AUTOSAR XML (schema 00046)
package /ComponentTypes
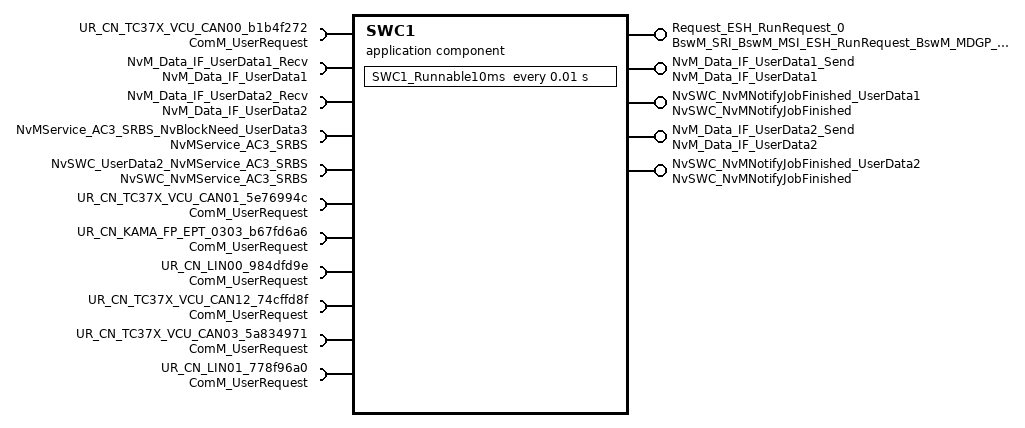
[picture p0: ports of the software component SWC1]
  application sw component type SWC1
    provide port Request_ESH_RunRequest_0: nonqueued-sender-com-spec=requestedMode, provided-interface=BswM_SRI_BswM_MSI_ESH_RunRequest_BswM_MDGP_ESH_RunRequest
    require port UR_CN_TC37X_VCU_CAN00_b1b4f272: required-com-specs=[RequestComMode, GetCurrentComMode, GetMaxComMode, GetRequestedComMode], required-interface=ComM_UserRequest
    provide port NvM_Data_IF_UserData1_Send: nv-provide-com-spec{ram-block-init-value=10 x 0, rom-block-init-value=10 x 0, variable=Element_UserData1}, provided-interface=NvM_Data_IF_UserData1
    require port NvM_Data_IF_UserData1_Recv: nv-require-com-spec{init-value=10 x 0, variable=Element_UserData1}, required-interface=NvM_Data_IF_UserData1
    provide port NvSWC_NvMNotifyJobFinished_UserData1: server-com-spec{operation=JobFinished, queue-length=1}, provided-interface=NvSWC_NvMNotifyJobFinished
    provide port NvM_Data_IF_UserData2_Send: nv-provide-com-spec=Element_UserData2, provided-interface=NvM_Data_IF_UserData2
    require port NvM_Data_IF_UserData2_Recv: nv-require-com-spec=Element_UserData2, required-interface=NvM_Data_IF_UserData2
    provide port NvSWC_NvMNotifyJobFinished_UserData2: server-com-spec{operation=JobFinished, queue-length=1}, provided-interface=NvSWC_NvMNotifyJobFinished
    8 x require port:
      NvMService_AC3_SRBS_NvBlockNeed_UserData3: required-com-specs=[WriteBlock, SetRamBlockStatus, ReadBlock, InvalidateNvBlock, GetErrorStatus, EraseBlock], required-interface=NvMService_AC3_SRBS
      NvSWC_UserData2_NvMService_AC3_SRBS: required-com-specs=[WriteBlock, SetRamBlockStatus, ReadBlock, InvalidateNvBlock, GetErrorStatus, EraseBlock], required-interface=NvSWC_NvMService_AC3_SRBS
      UR_CN_TC37X_VCU_CAN01_5e76994c: required-com-specs=[RequestComMode, GetCurrentComMode, GetMaxComMode, GetRequestedComMode], required-interface=ComM_UserRequest
      UR_CN_KAMA_FP_EPT_0303_b67fd6a6: required-com-specs=[RequestComMode, GetCurrentComMode, GetMaxComMode, GetRequestedComMode], required-interface=ComM_UserRequest
      UR_CN_LIN00_984dfd9e: required-com-specs=[RequestComMode, GetCurrentComMode, GetMaxComMode, GetRequestedComMode], required-interface=ComM_UserRequest
      UR_CN_TC37X_VCU_CAN12_74cffd8f: required-com-specs=[RequestComMode, GetCurrentComMode, GetMaxComMode, GetRequestedComMode], required-interface=ComM_UserRequest
      UR_CN_TC37X_VCU_CAN03_5a834971: required-com-specs=[RequestComMode, GetCurrentComMode, GetMaxComMode, GetRequestedComMode], required-interface=ComM_UserRequest
      UR_CN_LIN01_778f96a0: required-com-specs=[RequestComMode, GetCurrentComMode, GetMaxComMode, GetRequestedComMode], required-interface=ComM_UserRequest
    behavior SWC1_InternalBehavior
      ar-typed-per-instance-memorys:
        data NvBlockNeed_UserData3_MirrorBlock: sw-calibration-access=READ-ONLY, type=NvM_Array10Bytes
      init event SWC1_InitEvent: start-on-event=SWC1_Init
      timing event TMT_SWC1_Runnable10ms: start-on-event=SWC1_Runnable10ms, period=0.01
      operation invoked event OIT_NvSWC_NvMNotifyJobFinished_UserData1_JobFinished_NvSWC_NvMNotifyJobFinished_UserData1_JobFinished: start-on-event=NvSWC_NvMNotifyJobFinished_UserData1_JobFinished, operation=NvSWC_NvMNotifyJobFinished_UserData1.JobFinished
      operation invoked event OIT_NvSWC_NvMNotifyJobFinished_UserData2_JobFinished_NvSWC_NvMNotifyJobFinished_UserData2_JobFinished: start-on-event=NvSWC_NvMNotifyJobFinished_UserData2_JobFinished, operation=NvSWC_NvMNotifyJobFinished_UserData2.JobFinished
      4 x runnable:
        SWC1_Init
          data-send-points:
            access SEND_Request_ESH_RunRequest_0_requestedMode: accessed-variable=Request_ESH_RunRequest_0.requestedMode
        SWC1_Runnable10ms
          data-receive-point-by-arguments:
            access REC_NvM_Data_IF_UserData1_Recv_Element_UserData1: accessed-variable=NvM_Data_IF_UserData1_Recv.Element_UserData1
            access REC_NvM_Data_IF_UserData2_Recv_Element_UserData2: accessed-variable=NvM_Data_IF_UserData2_Recv.Element_UserData2
          data-send-points:
            access SEND_NvM_Data_IF_UserData1_Send_Element_UserData1: accessed-variable=NvM_Data_IF_UserData1_Send.Element_UserData1
            access SEND_NvM_Data_IF_UserData2_Send_Element_UserData2: accessed-variable=NvM_Data_IF_UserData2_Send.Element_UserData2
          17 x sync call:
            SC_UR_CN_TC37X_VCU_CAN00_b1b4f272_RequestComMode: operation=UR_CN_TC37X_VCU_CAN00_b1b4f272.RequestComMode
            SC_NvMService_AC3_SRBS_NvBlockNeed_UserData3_ReadBlock: operation=NvMService_AC3_SRBS_NvBlockNeed_UserData3.ReadBlock
            SC_NvMService_AC3_SRBS_NvBlockNeed_UserData3_SetRamBlockStatus: operation=NvMService_AC3_SRBS_NvBlockNeed_UserData3.SetRamBlockStatus
            SC_NvMService_AC3_SRBS_NvBlockNeed_UserData3_WriteBlock: operation=NvMService_AC3_SRBS_NvBlockNeed_UserData3.WriteBlock
            SC_NvSWC_NvMService_AC3_SRBS_SetRamBlockStatus: operation=NvSWC_UserData2_NvMService_AC3_SRBS.SetRamBlockStatus
            SC_UR_CN_TC37X_VCU_CAN01_5e76994c_GetCurrentComMode: operation=UR_CN_TC37X_VCU_CAN01_5e76994c.GetCurrentComMode
            SC_UR_CN_TC37X_VCU_CAN01_5e76994c_RequestComMode: operation=UR_CN_TC37X_VCU_CAN01_5e76994c.RequestComMode
            SC_UR_CN_KAMA_FP_EPT_0303_b67fd6a6_GetCurrentComMode: operation=UR_CN_KAMA_FP_EPT_0303_b67fd6a6.GetCurrentComMode
            SC_UR_CN_KAMA_FP_EPT_0303_b67fd6a6_RequestComMode: operation=UR_CN_KAMA_FP_EPT_0303_b67fd6a6.RequestComMode
            SC_UR_CN_LIN00_984dfd9e_RequestComMode: operation=UR_CN_LIN00_984dfd9e.RequestComMode
            SC_UR_CN_TC37X_VCU_CAN00_b1b4f272_GetCurrentComMode: operation=UR_CN_TC37X_VCU_CAN00_b1b4f272.GetCurrentComMode
            SC_UR_CN_TC37X_VCU_CAN12_74cffd8f_GetCurrentComMode: operation=UR_CN_TC37X_VCU_CAN12_74cffd8f.GetCurrentComMode
            SC_UR_CN_TC37X_VCU_CAN12_74cffd8f_RequestComMode: operation=UR_CN_TC37X_VCU_CAN12_74cffd8f.RequestComMode
            SC_UR_CN_TC37X_VCU_CAN03_5a834971_GetCurrentComMode: operation=UR_CN_TC37X_VCU_CAN03_5a834971.GetCurrentComMode
            SC_UR_CN_TC37X_VCU_CAN03_5a834971_RequestComMode: operation=UR_CN_TC37X_VCU_CAN03_5a834971.RequestComMode
            SC_UR_CN_LIN01_778f96a0_GetCurrentComMode: operation=UR_CN_LIN01_778f96a0.GetCurrentComMode
            SC_UR_CN_LIN01_778f96a0_RequestComMode: operation=UR_CN_LIN01_778f96a0.RequestComMode
        NvSWC_NvMNotifyJobFinished_UserData1_JobFinished
        NvSWC_NvMNotifyJobFinished_UserData2_JobFinished
      swc service dependency NvBlockNeed_UserData3: assigned-ports=role-based-port-assignment={port-prototype=NvMService_AC3_SRBS_NvBlockNeed_UserData3, role=NvMService_AC3_SRBS}
        assigned-datas:
          role=ramBlock, used-data-element=NvBlockNeed_UserData3_MirrorBlock
          role=defaultValue, used-parameter-element=NvBlockNeed_UserData3_DefaultValue
        service-needs:
          nv block needs NvBlockNeed_UserData3: calc-ram-block-crc=false, check-static-block-id=false, n-data-sets=1, n-rom-blocks=1, ram-block-status-control=API, readonly=false, reliability=ERROR-DETECTION, resistant-to-changed-sw=true, restore-at-start=true, store-at-shutdown=true, store-cyclic=false, store-emergency=false, store-immediate=false, use-auto-validation-at-shut-down=false, use-crc-comp-mechanism=false, write-only-once=false, write-verification=false
      shared-parameters:
        parameter data prototype NvBlockNeed_UserData3_DefaultValue: sw-calibration-access=READ-WRITE, type=NvM_Array10Bytes, init-value=10 x 0
        parameter data prototype CalibrationParameter: sw-calibration-access=READ-WRITE, type=uint16, init-value=7
  swc implementation SWC1_Implementation: behavior=SWC1_InternalBehavior
